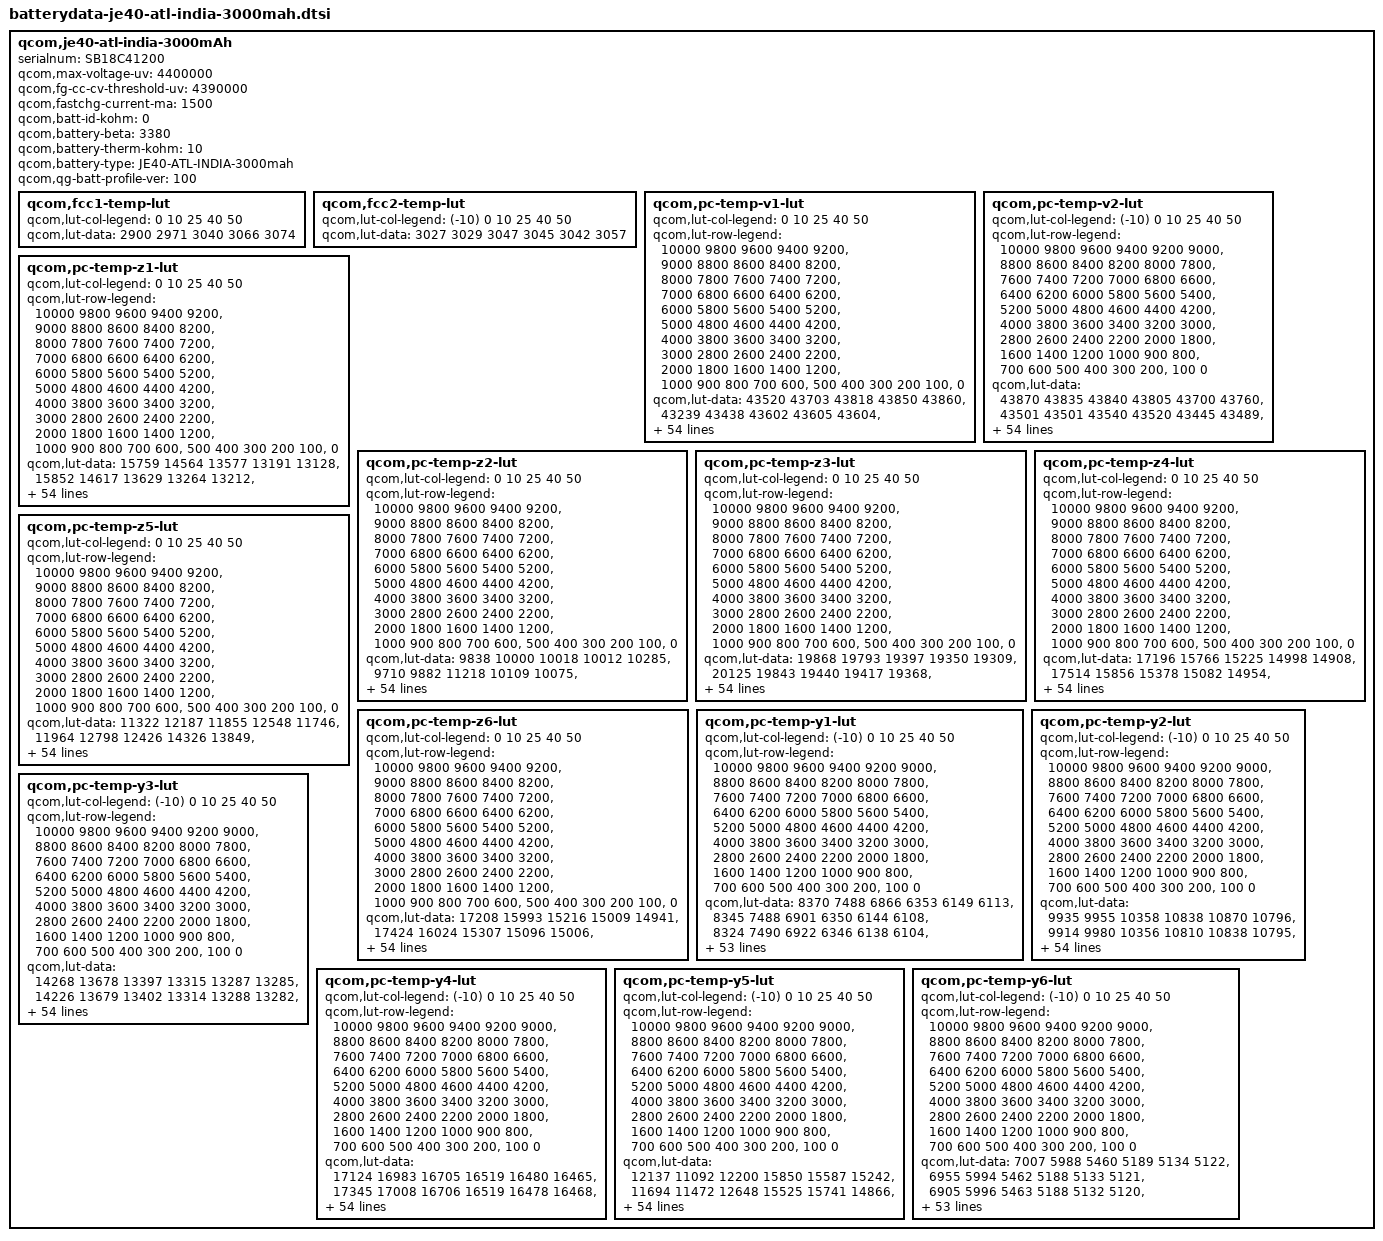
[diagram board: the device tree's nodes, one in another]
/* Copyright (c) 2018, The Linux Foundation. All rights reserved.
 *
 * This program is free software; you can redistribute it and/or modify
 * it under the terms of the GNU General Public License version 2 and
 * only version 2 as published by the Free Software Foundation.
 *
 * This program is distributed in the hope that it will be useful,
 * but WITHOUT ANY WARRANTY; without even the implied warranty of
 * MERCHANTABILITY or FITNESS FOR A PARTICULAR PURPOSE.  See the
 * GNU General Public License for more details.
 */

qcom,je40-atl-india-3000mAh {
    serialnum = "SB18C41200";
    qcom,max-voltage-uv = <4400000>;
    qcom,fg-cc-cv-threshold-uv = <4390000>;
    qcom,fastchg-current-ma = <1500>;
    qcom,batt-id-kohm = <0>;
    qcom,battery-beta = <3380>;
    qcom,battery-therm-kohm = <10>;
    qcom,battery-type = "JE40-ATL-INDIA-3000mah";
    qcom,qg-batt-profile-ver = <100>;

	qcom,fcc1-temp-lut {
		qcom,lut-col-legend = <0 10 25 40 50>;
		qcom,lut-data = <2900 2971 3040 3066 3074>;
	};

	qcom,fcc2-temp-lut {
		qcom,lut-col-legend = <(-10) 0 10 25 40 50>;
		qcom,lut-data = <3027 3029 3047 3045 3042 3057>;
	};

	qcom,pc-temp-v1-lut {
		qcom,lut-col-legend = <0 10 25 40 50>;
		qcom,lut-row-legend = <10000 9800 9600 9400 9200>,
			<9000 8800 8600 8400 8200>,
			<8000 7800 7600 7400 7200>,
			<7000 6800 6600 6400 6200>,
			<6000 5800 5600 5400 5200>,
			<5000 4800 4600 4400 4200>,
			<4000 3800 3600 3400 3200>,
			<3000 2800 2600 2400 2200>,
			<2000 1800 1600 1400 1200>,
			<1000 900 800 700 600>,
			<500 400 300 200 100>,
			<0>;
		qcom,lut-data = <43520 43703 43818 43850 43860>,
			<43239 43438 43602 43605 43604>,
			<42990 43182 43359 43372 43374>,
			<42756 42937 43108 43140 43144>,
			<42524 42699 42863 42906 42913>,
			<42295 42464 42619 42670 42678>,
			<42070 42233 42381 42435 42444>,
			<41849 42006 42147 42200 42213>,
			<41633 41783 41918 41968 41985>,
			<41428 41564 41693 41740 41757>,
			<41241 41355 41471 41515 41529>,
			<41050 41160 41258 41296 41307>,
			<40832 40962 41057 41081 41088>,
			<40594 40746 40855 40873 40877>,
			<40370 40520 40642 40666 40671>,
			<40158 40312 40429 40463 40471>,
			<39964 40120 40233 40271 40280>,
			<39805 39944 40050 40092 40099>,
			<39672 39794 39881 39922 39926>,
			<39544 39660 39741 39766 39765>,
			<39414 39522 39601 39619 39614>,
			<39287 39382 39404 39432 39433>,
			<39162 39230 39137 39155 39183>,
			<39040 39030 38915 38910 38947>,
			<38922 38792 38761 38776 38799>,
			<38809 38622 38639 38676 38685>,
			<38701 38515 38547 38579 38577>,
			<38598 38434 38475 38484 38475>,
			<38496 38374 38407 38395 38380>,
			<38405 38329 38340 38310 38291>,
			<38336 38286 38276 38232 38210>,
			<38280 38243 38217 38164 38138>,
			<38234 38203 38163 38105 38075>,
			<38197 38167 38114 38051 38016>,
			<38167 38135 38073 38003 37963>,
			<38136 38102 38034 37958 37912>,
			<38109 38073 37996 37910 37855>,
			<38076 38039 37957 37863 37792>,
			<38026 37987 37903 37802 37721>,
			<37957 37904 37815 37718 37639>,
			<37872 37805 37710 37617 37545>,
			<37754 37688 37596 37505 37434>,
			<37619 37553 37467 37376 37304>,
			<37464 37397 37310 37219 37150>,
			<37330 37256 37167 37078 37010>,
			<37236 37158 37078 36991 36927>,
			<37200 37128 37051 36968 36904>,
			<37175 37108 37033 36952 36887>,
			<37151 37093 37020 36935 36870>,
			<37110 37055 36978 36882 36807>,
			<36923 36834 36737 36622 36526>,
			<36485 36398 36304 36184 36084>,
			<35915 35822 35732 35608 35506>,
			<35141 35038 34950 34821 34715>,
			<33921 33802 33729 33596 33482>,
			<30000 30000 30000 30000 30000>;
	};

	qcom,pc-temp-v2-lut {
		qcom,lut-col-legend = <(-10) 0 10 25 40 50>;
		qcom,lut-row-legend = <10000 9800 9600 9400 9200 9000>,
			<8800 8600 8400 8200 8000 7800>,
			<7600 7400 7200 7000 6800 6600>,
			<6400 6200 6000 5800 5600 5400>,
			<5200 5000 4800 4600 4400 4200>,
			<4000 3800 3600 3400 3200 3000>,
			<2800 2600 2400 2200 2000 1800>,
			<1600 1400 1200 1000 900 800>,
			<700 600 500 400 300 200>,
			<100 0>;
		qcom,lut-data = <43870 43835 43840 43805 43700 43760>,
			<43501 43501 43540 43520 43445 43489>,
			<43164 43192 43258 43250 43195 43228>,
			<42861 42911 42996 42996 42953 42982>,
			<42587 42657 42754 42757 42719 42749>,
			<42338 42411 42515 42522 42486 42517>,
			<42122 42165 42276 42286 42253 42284>,
			<41916 41926 42039 42053 42020 42053>,
			<41674 41694 41809 41823 41791 41823>,
			<41395 41467 41582 41597 41565 41595>,
			<41162 41254 41364 41373 41342 41370>,
			<41016 41063 41155 41155 41122 41149>,
			<40877 40877 40952 40940 40907 40933>,
			<40640 40679 40751 40734 40703 40725>,
			<40281 40472 40551 40534 40505 40522>,
			<39956 40236 40341 40335 40312 40327>,
			<39699 39922 40117 40128 40117 40139>,
			<39474 39613 39889 39934 39931 39958>,
			<39289 39415 39665 39775 39765 39790>,
			<39132 39269 39444 39635 39612 39627>,
			<38978 39120 39241 39458 39432 39440>,
			<38823 38953 39054 39206 39197 39214>,
			<38675 38791 38885 38961 38969 38999>,
			<38536 38649 38736 38789 38795 38819>,
			<38405 38520 38602 38645 38645 38659>,
			<38297 38394 38481 38521 38518 38527>,
			<38213 38259 38372 38412 38411 38417>,
			<38141 38142 38272 38314 38314 38317>,
			<38073 38065 38180 38221 38225 38224>,
			<38011 38006 38095 38135 38143 38138>,
			<37952 37955 38012 38059 38070 38062>,
			<37895 37911 37930 37990 38003 37992>,
			<37839 37870 37864 37927 37938 37925>,
			<37783 37827 37818 37867 37873 37864>,
			<37728 37784 37781 37812 37806 37800>,
			<37671 37739 37743 37755 37730 37710>,
			<37609 37690 37706 37697 37641 37592>,
			<37547 37637 37663 37634 37553 37485>,
			<37481 37575 37607 37564 37472 37399>,
			<37413 37507 37540 37487 37390 37316>,
			<37345 37429 37459 37403 37303 37229>,
			<37278 37337 37357 37306 37208 37136>,
			<37210 37231 37236 37190 37091 37016>,
			<37139 37109 37102 37055 36958 36880>,
			<37058 36997 36973 36924 36850 36783>,
			<36955 36900 36890 36885 36823 36763>,
			<36902 36856 36862 36869 36810 36748>,
			<36837 36817 36834 36849 36792 36725>,
			<36744 36765 36790 36815 36747 36662>,
			<36579 36678 36695 36708 36585 36407>,
			<36300 36478 36430 36390 36172 35966>,
			<35871 36063 35924 35870 35626 35383>,
			<35255 35449 35260 35206 34908 34606>,
			<34327 34582 34328 34273 33916 33557>,
			<32758 33149 32927 33037 32736 32451>,
			<28894 29706 27951 28120 28055 28405>;
	};

	qcom,pc-temp-z1-lut {
		qcom,lut-col-legend = <0 10 25 40 50>;
		qcom,lut-row-legend = <10000 9800 9600 9400 9200>,
			<9000 8800 8600 8400 8200>,
			<8000 7800 7600 7400 7200>,
			<7000 6800 6600 6400 6200>,
			<6000 5800 5600 5400 5200>,
			<5000 4800 4600 4400 4200>,
			<4000 3800 3600 3400 3200>,
			<3000 2800 2600 2400 2200>,
			<2000 1800 1600 1400 1200>,
			<1000 900 800 700 600>,
			<500 400 300 200 100>,
			<0>;
		qcom,lut-data = <15759 14564 13577 13191 13128>,
			<15852 14617 13629 13264 13212>,
			<15836 14646 13632 13274 13223>,
			<15812 14648 13632 13279 13230>,
			<15800 14643 13626 13279 13232>,
			<15797 14632 13613 13277 13234>,
			<15795 14601 13603 13276 13235>,
			<15761 14574 13594 13276 13237>,
			<15705 14566 13587 13277 13241>,
			<15693 14560 13585 13278 13243>,
			<15734 14554 13584 13281 13245>,
			<15772 14549 13583 13282 13247>,
			<15748 14543 13583 13282 13247>,
			<15672 14515 13583 13282 13248>,
			<15617 14466 13579 13282 13249>,
			<15590 14451 13574 13280 13249>,
			<15569 14464 13574 13280 13250>,
			<15550 14477 13576 13282 13251>,
			<15533 14480 13579 13285 13252>,
			<15524 14483 13585 13288 13254>,
			<15528 14487 13594 13292 13257>,
			<15536 14499 13599 13294 13259>,
			<15541 14511 13602 13296 13262>,
			<15557 14521 13606 13298 13264>,
			<15572 14529 13613 13302 13267>,
			<15580 14536 13622 13308 13271>,
			<15587 14542 13630 13313 13276>,
			<15592 14547 13638 13317 13281>,
			<15596 14551 13646 13322 13285>,
			<15601 14554 13654 13328 13290>,
			<15612 14559 13661 13334 13294>,
			<15637 14568 13669 13340 13298>,
			<15652 14579 13675 13344 13302>,
			<15650 14590 13683 13349 13306>,
			<15646 14605 13690 13355 13310>,
			<15651 14616 13698 13361 13313>,
			<15663 14628 13707 13366 13316>,
			<15680 14642 13718 13370 13319>,
			<15711 14657 13729 13375 13322>,
			<15749 14678 13740 13380 13327>,
			<15762 14696 13750 13385 13331>,
			<15752 14706 13759 13391 13335>,
			<15747 14715 13768 13396 13338>,
			<15758 14726 13777 13401 13342>,
			<15787 14736 13792 13408 13346>,
			<15803 14732 13802 13412 13349>,
			<15782 14728 13796 13412 13351>,
			<15783 14759 13798 13414 13352>,
			<15808 14762 13804 13417 13355>,
			<15824 14730 13810 13421 13359>,
			<15866 14801 13821 13428 13366>,
			<15886 14808 13841 13440 13376>,
			<15866 14844 13865 13455 13390>,
			<15982 14889 13894 13478 13410>,
			<15982 14889 13894 13478 13410>,
			<15982 14889 13894 13478 13410>;
	};

	qcom,pc-temp-z2-lut {
		qcom,lut-col-legend = <0 10 25 40 50>;
		qcom,lut-row-legend = <10000 9800 9600 9400 9200>,
			<9000 8800 8600 8400 8200>,
			<8000 7800 7600 7400 7200>,
			<7000 6800 6600 6400 6200>,
			<6000 5800 5600 5400 5200>,
			<5000 4800 4600 4400 4200>,
			<4000 3800 3600 3400 3200>,
			<3000 2800 2600 2400 2200>,
			<2000 1800 1600 1400 1200>,
			<1000 900 800 700 600>,
			<500 400 300 200 100>,
			<0>;
		qcom,lut-data = <9838 10000 10018 10012 10285>,
			<9710 9882 11218 10109 10075>,
			<9728 9815 10902 10147 10144>,
			<9761 9799 10517 10208 10242>,
			<9787 9785 10267 10219 10270>,
			<9814 9774 10061 10202 10263>,
			<9830 9763 10001 10185 10252>,
			<9831 9757 9985 10174 10225>,
			<9831 9757 9978 10164 10182>,
			<9831 9757 10038 10156 10152>,
			<9828 9757 10146 10150 10118>,
			<9823 9759 10173 10146 10100>,
			<9805 9763 10177 10151 10089>,
			<9768 9769 10180 10159 10072>,
			<9752 9778 10185 10139 10075>,
			<9752 9795 10190 10076 10087>,
			<9753 9843 10175 10049 10095>,
			<9756 9887 10094 10055 10101>,
			<9765 9897 10047 10064 10109>,
			<9771 9898 10061 10075 10119>,
			<9765 9897 10085 10091 10138>,
			<9755 9894 10099 10119 10143>,
			<9748 9891 10111 10200 10133>,
			<9743 9892 10115 10261 10123>,
			<9740 9894 10092 10207 10130>,
			<9741 9897 10064 10100 10153>,
			<9745 9901 10063 10085 10176>,
			<9749 9904 10072 10155 10206>,
			<9754 9901 10079 10212 10225>,
			<9760 9892 10094 10220 10193>,
			<9766 9888 10109 10213 10132>,
			<9772 9894 10107 10198 10106>,
			<9779 9902 10100 10173 10076>,
			<9786 9907 10097 10161 10061>,
			<9794 9911 10101 10183 10076>,
			<9805 9915 10106 10219 10105>,
			<9821 9920 10113 10244 10157>,
			<9835 9925 10122 10269 10267>,
			<9844 9931 10135 10293 10313>,
			<9852 9938 10159 10322 10275>,
			<9860 9943 10176 10343 10235>,
			<9871 9946 10173 10344 10233>,
			<9888 9950 10170 10339 10234>,
			<9926 9967 10174 10327 10231>,
			<10138 10097 10211 10307 10230>,
			<10107 10183 10256 10260 10239>,
			<10090 10192 10253 10258 10251>,
			<10079 10224 10249 10253 10234>,
			<10029 10396 10308 10259 10260>,
			<10031 10435 10331 10349 10374>,
			<10040 10285 10344 10332 10186>,
			<9972 10255 10327 10237 10093>,
			<9811 10216 10270 10194 10018>,
			<9678 10039 10268 10115 9972>,
			<9678 10039 10268 10115 9972>,
			<9678 10039 10268 10115 9972>;
	};

	qcom,pc-temp-z3-lut {
		qcom,lut-col-legend = <0 10 25 40 50>;
		qcom,lut-row-legend = <10000 9800 9600 9400 9200>,
			<9000 8800 8600 8400 8200>,
			<8000 7800 7600 7400 7200>,
			<7000 6800 6600 6400 6200>,
			<6000 5800 5600 5400 5200>,
			<5000 4800 4600 4400 4200>,
			<4000 3800 3600 3400 3200>,
			<3000 2800 2600 2400 2200>,
			<2000 1800 1600 1400 1200>,
			<1000 900 800 700 600>,
			<500 400 300 200 100>,
			<0>;
		qcom,lut-data = <19868 19793 19397 19350 19309>,
			<20125 19843 19440 19417 19368>,
			<20140 19876 19511 19440 19394>,
			<20147 19894 19569 19454 19412>,
			<20130 19912 19581 19459 19425>,
			<20037 19914 19587 19465 19437>,
			<19957 19897 19588 19467 19444>,
			<19932 19875 19582 19467 19440>,
			<19916 19854 19575 19466 19429>,
			<19913 19832 19577 19461 19421>,
			<19913 19817 19583 19443 19414>,
			<19913 19809 19578 19431 19408>,
			<19935 19800 19558 19427 19400>,
			<19991 19784 19545 19424 19391>,
			<20016 19763 19543 19417 19385>,
			<20007 19749 19541 19402 19380>,
			<19991 19741 19535 19395 19376>,
			<19973 19735 19510 19394 19373>,
			<19949 19714 19494 19393 19370>,
			<19937 19673 19491 19390 19367>,
			<19952 19660 19489 19384 19363>,
			<19982 19680 19497 19384 19362>,
			<20008 19710 19528 19405 19369>,
			<20033 19742 19543 19423 19376>,
			<20050 19778 19534 19409 19368>,
			<20055 19791 19518 19382 19350>,
			<20057 19789 19508 19377 19348>,
			<20060 19786 19499 19387 19378>,
			<20064 19779 19496 19401 19404>,
			<20068 19765 19503 19423 19412>,
			<20064 19753 19513 19447 19417>,
			<20049 19744 19521 19449 19415>,
			<20031 19736 19530 19441 19406>,
			<20010 19731 19533 19432 19396>,
			<19986 19727 19529 19426 19387>,
			<19958 19722 19522 19420 19380>,
			<19922 19713 19517 19416 19380>,
			<19898 19704 19512 19412 19383>,
			<19892 19700 19507 19409 19384>,
			<19888 19698 19504 19408 19380>,
			<19882 19695 19500 19406 19375>,
			<19868 19690 19497 19404 19374>,
			<19848 19683 19492 19401 19375>,
			<19814 19657 19485 19399 19372>,
			<19566 19580 19468 19391 19368>,
			<19378 19527 19444 19378 19357>,
			<19375 19522 19440 19371 19352>,
			<19366 19499 19438 19367 19350>,
			<19352 19367 19388 19364 19340>,
			<19344 19361 19393 19354 19331>,
			<19360 19498 19404 19357 19369>,
			<19372 19492 19408 19367 19375>,
			<19385 19475 19395 19368 19376>,
			<19395 19390 19376 19377 19385>,
			<19395 19390 19376 19377 19385>,
			<19395 19390 19376 19377 19385>;
	};

	qcom,pc-temp-z4-lut {
		qcom,lut-col-legend = <0 10 25 40 50>;
		qcom,lut-row-legend = <10000 9800 9600 9400 9200>,
			<9000 8800 8600 8400 8200>,
			<8000 7800 7600 7400 7200>,
			<7000 6800 6600 6400 6200>,
			<6000 5800 5600 5400 5200>,
			<5000 4800 4600 4400 4200>,
			<4000 3800 3600 3400 3200>,
			<3000 2800 2600 2400 2200>,
			<2000 1800 1600 1400 1200>,
			<1000 900 800 700 600>,
			<500 400 300 200 100>,
			<0>;
		qcom,lut-data = <17196 15766 15225 14998 14908>,
			<17514 15856 15378 15082 14954>,
			<17249 15843 15284 15070 14970>,
			<16821 15689 15168 15009 14938>,
			<16563 15462 15095 14961 14907>,
			<16393 15314 15033 14924 14874>,
			<16246 15216 14982 14890 14845>,
			<16105 15142 14940 14859 14827>,
			<15977 15090 14900 14833 14813>,
			<15864 15049 14848 14816 14799>,
			<15764 15011 14798 14806 14784>,
			<15670 14972 14778 14795 14773>,
			<15570 14942 14770 14779 14767>,
			<15470 14924 14763 14765 14761>,
			<15394 14911 14757 14763 14754>,
			<15344 14898 14751 14763 14744>,
			<15302 14867 14749 14761 14734>,
			<15259 14843 14755 14744 14723>,
			<15218 14848 14754 14726 14713>,
			<15172 14861 14741 14721 14706>,
			<15108 14857 14727 14718 14702>,
			<15037 14824 14744 14725 14705>,
			<14984 14796 14824 14818 14791>,
			<14940 14822 14887 14903 14878>,
			<14911 14897 14918 14916 14893>,
			<14900 14928 14937 14923 14900>,
			<14893 14926 14934 14920 14896>,
			<14891 14923 14913 14887 14844>,
			<14893 14914 14888 14846 14790>,
			<14894 14892 14858 14800 14759>,
			<14894 14871 14825 14755 14734>,
			<14892 14856 14798 14737 14721>,
			<14890 14841 14774 14727 14712>,
			<14888 14826 14760 14723 14709>,
			<14886 14811 14753 14723 14710>,
			<14888 14801 14749 14723 14711>,
			<14898 14794 14746 14725 14714>,
			<14905 14789 14744 14730 14723>,
			<14893 14788 14744 14737 14731>,
			<14871 14790 14755 14746 14738>,
			<14864 14790 14765 14753 14743>,
			<14866 14787 14759 14747 14738>,
			<14867 14785 14749 14737 14728>,
			<14857 14796 14749 14740 14733>,
			<14971 14792 14738 14736 14730>,
			<15119 14792 14714 14711 14708>,
			<15117 14789 14704 14702 14698>,
			<15122 14805 14692 14684 14675>,
			<15129 14944 14732 14666 14661>,
			<15120 14946 14725 14678 14674>,
			<15101 14800 14741 14716 14674>,
			<15121 14826 14747 14713 14676>,
			<15137 14858 14769 14716 14680>,
			<15151 14973 14795 14710 14675>,
			<15151 14973 14795 14710 14675>,
			<15151 14973 14795 14710 14675>;
	};

	qcom,pc-temp-z5-lut {
		qcom,lut-col-legend = <0 10 25 40 50>;
		qcom,lut-row-legend = <10000 9800 9600 9400 9200>,
			<9000 8800 8600 8400 8200>,
			<8000 7800 7600 7400 7200>,
			<7000 6800 6600 6400 6200>,
			<6000 5800 5600 5400 5200>,
			<5000 4800 4600 4400 4200>,
			<4000 3800 3600 3400 3200>,
			<3000 2800 2600 2400 2200>,
			<2000 1800 1600 1400 1200>,
			<1000 900 800 700 600>,
			<500 400 300 200 100>,
			<0>;
		qcom,lut-data = <11322 12187 11855 12548 11746>,
			<11964 12798 12426 14326 13849>,
			<12134 13301 13313 14863 14593>,
			<12222 13750 14214 15292 15379>,
			<12213 14191 14808 15518 16086>,
			<12108 14392 15305 15760 16834>,
			<12032 14496 15612 16009 17268>,
			<12045 14545 15782 16324 16986>,
			<12080 14540 16021 16622 16409>,
			<12119 14521 17222 16592 16283>,
			<12162 14549 18990 16243 16492>,
			<12226 14870 19341 16055 16645>,
			<12426 15263 19100 16431 16509>,
			<12805 15513 18935 16902 16278>,
			<12993 15730 19240 16698 16263>,
			<13023 15984 19724 15855 16430>,
			<13040 16599 19590 15522 16663>,
			<13057 17080 18522 16323 17191>,
			<13096 16598 18177 17330 17876>,
			<13166 15448 19009 17717 18393>,
			<13646 15278 20536 17961 18851>,
			<14635 17106 25028 18810 19315>,
			<15806 20293 36243 23339 20113>,
			<17480 26478 41680 26974 20697>,
			<19253 36357 35146 23718 18950>,
			<20745 40012 25887 17132 15016>,
			<22198 37204 21799 15219 13991>,
			<23883 33040 19153 15069 14985>,
			<26445 29727 18335 15227 16283>,
			<28439 26533 18664 17146 17891>,
			<28370 24629 19307 20391 19893>,
			<27358 23594 20859 22479 21258>,
			<26082 22999 24049 24021 22369>,
			<24429 22993 26331 25162 23078>,
			<22470 23148 27867 26471 23530>,
			<20612 23219 28745 27543 23913>,
			<18556 22746 28648 27428 24231>,
			<17427 22149 28212 26499 24736>,
			<17744 22184 27618 25328 24863>,
			<18375 22641 26248 23442 22435>,
			<18567 22889 24816 21651 19645>,
			<18503 22541 24020 20904 19118>,
			<18489 21787 23296 20385 18929>,
			<18485 19790 21772 19465 17841>,
			<14660 17746 21401 18774 17422>,
			<11549 16164 20357 18577 16930>,
			<11511 15867 20214 18015 16739>,
			<11414 14868 20184 18226 17862>,
			<11306 11765 14733 19400 18106>,
			<11293 11768 15178 17352 15878>,
			<11491 15135 15344 14721 17835>,
			<11504 14249 14928 14881 17578>,
			<11429 13403 13875 14525 16873>,
			<11357 11748 12933 14896 17623>,
			<11357 11748 12933 14896 17623>,
			<11357 11748 12933 14896 17623>;
	};

	qcom,pc-temp-z6-lut {
		qcom,lut-col-legend = <0 10 25 40 50>;
		qcom,lut-row-legend = <10000 9800 9600 9400 9200>,
			<9000 8800 8600 8400 8200>,
			<8000 7800 7600 7400 7200>,
			<7000 6800 6600 6400 6200>,
			<6000 5800 5600 5400 5200>,
			<5000 4800 4600 4400 4200>,
			<4000 3800 3600 3400 3200>,
			<3000 2800 2600 2400 2200>,
			<2000 1800 1600 1400 1200>,
			<1000 900 800 700 600>,
			<500 400 300 200 100>,
			<0>;
		qcom,lut-data = <17208 15993 15216 15009 14941>,
			<17424 16024 15307 15096 15006>,
			<17295 16031 15298 15098 15022>,
			<17072 15979 15284 15083 15022>,
			<16904 15865 15263 15070 15022>,
			<16760 15780 15232 15056 15015>,
			<16639 15718 15205 15043 15005>,
			<16547 15666 15181 15031 14996>,
			<16470 15624 15159 15020 14985>,
			<16405 15589 15140 15008 14975>,
			<16350 15560 15123 14994 14966>,
			<16302 15538 15108 14983 14957>,
			<16257 15516 15094 14975 14949>,
			<16215 15490 15084 14968 14942>,
			<16177 15463 15079 14961 14935>,
			<16141 15443 15075 14954 14928>,
			<16108 15429 15068 14947 14922>,
			<16075 15417 15058 14939 14915>,
			<16042 15404 15049 14932 14909>,
			<16015 15392 15042 14927 14904>,
			<15994 15388 15037 14923 14900>,
			<15977 15390 15049 14927 14902>,
			<15972 15393 15102 14980 14944>,
			<15970 15417 15135 15025 14985>,
			<15969 15472 15143 15023 14985>,
			<15969 15495 15146 15015 14982>,
			<15971 15495 15143 15008 14979>,
			<15973 15495 15131 15001 14973>,
			<15979 15490 15119 14994 14966>,
			<15984 15476 15111 14988 14959>,
			<15984 15463 15105 14982 14951>,
			<15978 15454 15099 14975 14944>,
			<15971 15447 15095 14967 14936>,
			<15962 15441 15091 14961 14930>,
			<15952 15436 15087 14957 14925>,
			<15945 15432 15084 14954 14922>,
			<15938 15429 15081 14954 14923>,
			<15935 15426 15078 14955 14928>,
			<15934 15427 15078 14956 14932>,
			<15934 15433 15083 14959 14933>,
			<15934 15437 15088 14962 14933>,
			<15938 15439 15085 14960 14931>,
			<15939 15440 15080 14954 14928>,
			<15928 15438 15079 14955 14929>,
			<15865 15411 15070 14951 14927>,
			<15841 15389 15049 14934 14912>,
			<15839 15386 15043 14927 14905>,
			<15836 15381 15037 14916 14894>,
			<15834 15376 15030 14907 14882>,
			<15836 15379 15031 14909 14884>,
			<15849 15395 15046 14927 14906>,
			<15875 15413 15055 14934 14913>,
			<15910 15433 15063 14939 14918>,
			<15955 15462 15075 14947 14925>,
			<15955 15462 15075 14947 14925>,
			<15955 15462 15075 14947 14925>;
	};

	qcom,pc-temp-y1-lut {
		qcom,lut-col-legend = <(-10) 0 10 25 40 50>;
		qcom,lut-row-legend = <10000 9800 9600 9400 9200 9000>,
			<8800 8600 8400 8200 8000 7800>,
			<7600 7400 7200 7000 6800 6600>,
			<6400 6200 6000 5800 5600 5400>,
			<5200 5000 4800 4600 4400 4200>,
			<4000 3800 3600 3400 3200 3000>,
			<2800 2600 2400 2200 2000 1800>,
			<1600 1400 1200 1000 900 800>,
			<700 600 500 400 300 200>,
			<100 0>;
		qcom,lut-data = <8370 7488 6866 6353 6149 6113>,
			<8345 7488 6901 6350 6144 6108>,
			<8324 7490 6922 6346 6138 6104>,
			<8308 7494 6932 6342 6133 6100>,
			<8297 7499 6936 6337 6128 6096>,
			<8294 7502 6935 6333 6124 6093>,
			<8300 7507 6923 6329 6121 6092>,
			<8309 7512 6908 6324 6118 6090>,
			<8312 7509 6906 6319 6116 6088>,
			<8320 7498 6907 6313 6113 6085>,
			<8323 7492 6906 6310 6112 6083>,
			<8318 7492 6900 6307 6110 6082>,
			<8313 7494 6893 6305 6108 6081>,
			<8316 7498 6889 6304 6107 6080>,
			<8318 7504 6885 6302 6106 6079>,
			<8321 7509 6884 6302 6105 6078>,
			<8324 7513 6892 6303 6107 6078>,
			<8329 7516 6900 6305 6108 6078>,
			<8340 7550 6899 6306 6108 6079>,
			<8363 7644 6895 6307 6108 6080>,
			<8372 7680 6894 6309 6109 6080>,
			<8352 7601 6899 6313 6109 6080>,
			<8329 7514 6903 6317 6110 6081>,
			<8321 7500 6904 6321 6112 6081>,
			<8317 7496 6905 6325 6114 6083>,
			<8314 7495 6908 6330 6116 6084>,
			<8319 7500 6916 6334 6119 6086>,
			<8327 7505 6923 6340 6122 6088>,
			<8323 7504 6921 6346 6126 6090>,
			<8306 7502 6915 6354 6129 6092>,
			<8290 7499 6916 6361 6133 6095>,
			<8268 7494 6924 6369 6137 6099>,
			<8252 7489 6935 6376 6141 6102>,
			<8255 7488 6948 6381 6145 6105>,
			<8269 7487 6960 6386 6149 6108>,
			<8280 7485 6960 6392 6153 6110>,
			<8286 7479 6953 6397 6156 6112>,
			<8290 7475 6949 6402 6158 6113>,
			<8280 7475 6952 6407 6160 6115>,
			<8258 7476 6956 6411 6162 6117>,
			<8241 7483 6961 6416 6164 6118>,
			<8225 7496 6968 6421 6168 6120>,
			<8229 7496 6971 6426 6171 6123>,
			<8276 7482 6974 6434 6175 6126>,
			<8303 7521 6983 6444 6181 6130>,
			<8310 7536 6996 6453 6184 6132>,
			<8321 7524 6991 6457 6186 6133>,
			<8379 7571 6989 6462 6187 6133>,
			<8356 7537 7002 6474 6187 6133>,
			<8355 7539 7022 6479 6188 6136>,
			<8371 7551 7016 6480 6194 6142>,
			<8371 7543 7019 6498 6206 6153>,
			<8456 7580 7038 6541 6222 6166>,
			<8592 7602 7078 6577 6244 6187>,
			<8592 7602 7078 6577 6244 6187>,
			<8592 7602 7078 6577 6244 6187>;
	};

	qcom,pc-temp-y2-lut {
		qcom,lut-col-legend = <(-10) 0 10 25 40 50>;
		qcom,lut-row-legend = <10000 9800 9600 9400 9200 9000>,
			<8800 8600 8400 8200 8000 7800>,
			<7600 7400 7200 7000 6800 6600>,
			<6400 6200 6000 5800 5600 5400>,
			<5200 5000 4800 4600 4400 4200>,
			<4000 3800 3600 3400 3200 3000>,
			<2800 2600 2400 2200 2000 1800>,
			<1600 1400 1200 1000 900 800>,
			<700 600 500 400 300 200>,
			<100 0>;
		qcom,lut-data = <9935 9955 10358 10838 10870 10796>,
			<9914 9980 10356 10810 10838 10795>,
			<9908 10006 10353 10777 10806 10792>,
			<9915 10030 10350 10744 10778 10787>,
			<9931 10047 10347 10715 10759 10781>,
			<9952 10054 10343 10696 10752 10774>,
			<9981 10048 10338 10683 10758 10755>,
			<10021 10041 10334 10672 10768 10735>,
			<10081 10047 10337 10668 10773 10738>,
			<10177 10084 10347 10663 10774 10757>,
			<10222 10132 10353 10661 10773 10771>,
			<10219 10219 10354 10661 10771 10796>,
			<10216 10302 10355 10661 10770 10819>,
			<10233 10312 10381 10665 10778 10807>,
			<10303 10311 10456 10678 10799 10771>,
			<10365 10312 10499 10695 10827 10761>,
			<10411 10328 10511 10723 10865 10808>,
			<10442 10357 10519 10759 10912 10875>,
			<10319 10400 10529 10802 10967 10938>,
			<9905 10466 10539 10850 11029 11000>,
			<9707 10515 10552 10862 11046 11018>,
			<9693 10551 10572 10839 11014 11013>,
			<9685 10574 10594 10817 10970 10999>,
			<9679 10489 10612 10825 10924 10951>,
			<9674 10248 10630 10847 10873 10884>,
			<9670 10164 10649 10868 10862 10874>,
			<9667 10352 10671 10892 10887 10899>,
			<9665 10537 10685 10910 10925 10927>,
			<9664 10542 10688 10918 10974 10953>,
			<9663 10527 10689 10923 11034 10979>,
			<9662 10492 10693 10930 11074 11001>,
			<9662 10303 10705 10941 11112 11023>,
			<9661 10118 10712 10947 11132 11043>,
			<9661 9986 10700 10945 11121 11066>,
			<9660 9764 10679 10941 11097 11084>,
			<9659 9686 10664 10937 11075 11075>,
			<9659 9676 10653 10928 11051 11037>,
			<9658 9670 10640 10918 11026 11002>,
			<9658 9666 10621 10906 10998 10974>,
			<9657 9663 10598 10892 10972 10951>,
			<9657 9661 10575 10880 10951 10939>,
			<9657 9659 10549 10869 10929 10926>,
			<9656 9658 10507 10851 10935 10924>,
			<9656 9657 10449 10823 10941 10917>,
			<9655 9656 10404 10796 10864 10838>,
			<9655 9656 10349 10793 10866 10747>,
			<9655 9655 10316 10787 10859 10749>,
			<9655 9654 10286 10769 10848 10756>,
			<9654 9654 10255 10757 10851 10793>,
			<9654 9653 10218 10757 10847 10705>,
			<9653 9653 9955 10730 10794 10686>,
			<9652 9652 9695 10674 10740 10618>,
			<9650 9651 9665 10613 10703 10587>,
			<9648 9651 9656 10569 10648 10498>,
			<9648 9651 9656 10569 10648 10498>,
			<9648 9651 9656 10569 10648 10498>;
	};

	qcom,pc-temp-y3-lut {
		qcom,lut-col-legend = <(-10) 0 10 25 40 50>;
		qcom,lut-row-legend = <10000 9800 9600 9400 9200 9000>,
			<8800 8600 8400 8200 8000 7800>,
			<7600 7400 7200 7000 6800 6600>,
			<6400 6200 6000 5800 5600 5400>,
			<5200 5000 4800 4600 4400 4200>,
			<4000 3800 3600 3400 3200 3000>,
			<2800 2600 2400 2200 2000 1800>,
			<1600 1400 1200 1000 900 800>,
			<700 600 500 400 300 200>,
			<100 0>;
		qcom,lut-data = <14268 13678 13397 13315 13287 13285>,
			<14226 13679 13402 13314 13288 13282>,
			<14162 13680 13410 13314 13290 13281>,
			<14092 13680 13418 13314 13291 13281>,
			<14035 13680 13424 13315 13293 13282>,
			<14007 13678 13427 13316 13294 13283>,
			<14002 13666 13428 13317 13296 13287>,
			<13998 13649 13429 13319 13297 13291>,
			<13971 13653 13429 13320 13298 13292>,
			<13875 13677 13428 13321 13299 13293>,
			<13787 13689 13428 13322 13300 13294>,
			<13718 13627 13431 13325 13300 13295>,
			<13667 13547 13434 13327 13300 13296>,
			<13663 13544 13433 13327 13302 13296>,
			<13670 13567 13427 13328 13308 13296>,
			<13672 13578 13424 13328 13311 13296>,
			<13615 13552 13422 13327 13311 13299>,
			<13543 13517 13421 13327 13311 13302>,
			<13528 13501 13415 13329 13309 13302>,
			<13525 13492 13405 13335 13306 13300>,
			<13526 13479 13395 13337 13303 13298>,
			<13536 13454 13387 13329 13300 13294>,
			<13547 13431 13379 13321 13296 13290>,
			<13544 13421 13374 13316 13293 13287>,
			<13532 13413 13369 13313 13289 13284>,
			<13527 13410 13367 13312 13288 13284>,
			<13531 13398 13365 13311 13288 13283>,
			<13538 13387 13364 13311 13288 13283>,
			<13546 13384 13364 13310 13288 13282>,
			<13559 13383 13364 13309 13289 13281>,
			<13574 13383 13362 13309 13290 13281>,
			<13597 13392 13352 13311 13291 13282>,
			<13624 13406 13346 13312 13292 13283>,
			<13650 13419 13349 13313 13292 13284>,
			<13678 13433 13355 13313 13291 13286>,
			<13709 13447 13359 13314 13291 13285>,
			<13745 13460 13364 13314 13291 13283>,
			<13784 13475 13367 13314 13290 13283>,
			<13824 13498 13369 13312 13289 13283>,
			<13867 13530 13371 13309 13288 13283>,
			<13912 13567 13372 13309 13288 13284>,
			<13961 13614 13374 13310 13288 13284>,
			<14019 13668 13373 13311 13288 13285>,
			<14087 13733 13372 13312 13288 13284>,
			<14143 13802 13372 13311 13289 13282>,
			<14080 13788 13376 13313 13294 13291>,
			<14159 13862 13386 13314 13297 13295>,
			<14250 13951 13401 13318 13305 13299>,
			<14346 14038 13416 13327 13308 13301>,
			<14465 14127 13435 13331 13305 13294>,
			<14639 14216 13452 13330 13298 13296>,
			<14923 14355 13498 13332 13303 13300>,
			<15631 14607 13639 13343 13312 13305>,
			<17590 14998 13919 13357 13319 13312>,
			<17590 14998 13919 13357 13319 13312>,
			<17590 14998 13919 13357 13319 13312>;
	};

	qcom,pc-temp-y4-lut {
		qcom,lut-col-legend = <(-10) 0 10 25 40 50>;
		qcom,lut-row-legend = <10000 9800 9600 9400 9200 9000>,
			<8800 8600 8400 8200 8000 7800>,
			<7600 7400 7200 7000 6800 6600>,
			<6400 6200 6000 5800 5600 5400>,
			<5200 5000 4800 4600 4400 4200>,
			<4000 3800 3600 3400 3200 3000>,
			<2800 2600 2400 2200 2000 1800>,
			<1600 1400 1200 1000 900 800>,
			<700 600 500 400 300 200>,
			<100 0>;
		qcom,lut-data = <17124 16983 16705 16519 16480 16465>,
			<17345 17008 16706 16519 16478 16468>,
			<17479 17033 16707 16520 16477 16470>,
			<17546 17056 16709 16521 16476 16471>,
			<17571 17078 16710 16522 16476 16471>,
			<17574 17098 16711 16524 16476 16471>,
			<17494 17121 16711 16526 16477 16469>,
			<17382 17139 16711 16529 16481 16467>,
			<17373 17123 16715 16534 16484 16468>,
			<17417 17050 16728 16543 16490 16472>,
			<17474 17013 16741 16551 16498 16477>,
			<17608 17175 16752 16560 16507 16481>,
			<17747 17381 16765 16570 16517 16487>,
			<17664 17385 16806 16587 16523 16496>,
			<17294 17294 16883 16613 16527 16507>,
			<17101 17186 16911 16639 16534 16517>,
			<17090 17039 16883 16664 16548 16523>,
			<17085 16915 16836 16686 16569 16530>,
			<17095 16896 16780 16706 16602 16553>,
			<17126 16892 16709 16724 16648 16585>,
			<17138 16885 16666 16722 16658 16591>,
			<17082 16866 16640 16633 16598 16565>,
			<17010 16844 16624 16543 16531 16533>,
			<16978 16825 16618 16520 16504 16504>,
			<16956 16804 16614 16506 16486 16478>,
			<16949 16782 16611 16504 16482 16474>,
			<16950 16728 16609 16506 16486 16477>,
			<16953 16682 16607 16511 16493 16482>,
			<16955 16683 16599 16517 16501 16491>,
			<16956 16691 16588 16526 16512 16504>,
			<16956 16699 16586 16534 16524 16516>,
			<16950 16711 16586 16543 16540 16529>,
			<16944 16724 16586 16550 16550 16540>,
			<16943 16745 16590 16554 16551 16549>,
			<16943 16781 16596 16558 16551 16556>,
			<16942 16804 16605 16557 16546 16544>,
			<16940 16818 16618 16548 16520 16506>,
			<16939 16828 16630 16540 16500 16486>,
			<16944 16833 16641 16534 16496 16483>,
			<16958 16836 16650 16529 16493 16482>,
			<16973 16836 16650 16529 16495 16485>,
			<16992 16830 16649 16532 16501 16491>,
			<17014 16824 16646 16533 16501 16488>,
			<17041 16817 16640 16531 16494 16477>,
			<17047 16818 16625 16506 16471 16463>,
			<16979 16799 16630 16510 16484 16478>,
			<16992 16821 16652 16530 16501 16500>,
			<17009 16846 16683 16555 16522 16532>,
			<17030 16884 16731 16585 16549 16555>,
			<17035 16932 16790 16592 16537 16493>,
			<17026 16945 16811 16560 16494 16479>,
			<17019 16898 16822 16552 16498 16488>,
			<17139 16890 16872 16585 16522 16527>,
			<17830 16913 16971 16664 16656 16782>,
			<17830 16913 16971 16664 16656 16782>,
			<17830 16913 16971 16664 16656 16782>;
	};

	qcom,pc-temp-y5-lut {
		qcom,lut-col-legend = <(-10) 0 10 25 40 50>;
		qcom,lut-row-legend = <10000 9800 9600 9400 9200 9000>,
			<8800 8600 8400 8200 8000 7800>,
			<7600 7400 7200 7000 6800 6600>,
			<6400 6200 6000 5800 5600 5400>,
			<5200 5000 4800 4600 4400 4200>,
			<4000 3800 3600 3400 3200 3000>,
			<2800 2600 2400 2200 2000 1800>,
			<1600 1400 1200 1000 900 800>,
			<700 600 500 400 300 200>,
			<100 0>;
		qcom,lut-data = <12137 11092 12200 15850 15587 15242>,
			<11694 11472 12648 15525 15741 14866>,
			<11497 11873 13254 15174 15834 14640>,
			<11499 12231 13866 14835 15881 14526>,
			<11651 12487 14331 14546 15897 14486>,
			<11910 12579 14498 14344 15899 14493>,
			<13003 12496 14449 14227 15775 15458>,
			<14330 12380 14346 14118 15526 16675>,
			<14209 12603 14178 13921 15232 16707>,
			<12873 13599 13892 13609 14824 16281>,
			<12146 14123 13764 13381 14392 15838>,
			<12536 13247 13778 13273 13847 15448>,
			<13361 12132 13820 13203 13428 15028>,
			<14855 13085 13942 13004 13507 14460>,
			<17617 17003 14302 12544 13857 13802>,
			<18817 18855 14968 12373 13994 13615>,
			<16554 16769 17459 12657 13795 13820>,
			<13671 14329 19689 13237 13589 14006>,
			<12924 14365 19452 15045 13614 13813>,
			<12587 15219 18445 18375 13769 13386>,
			<12496 15586 17591 19575 14202 13539>,
			<12629 15405 16872 19662 16818 15802>,
			<12775 15139 16321 19661 19108 17541>,
			<12590 15260 15952 19021 18616 17476>,
			<11997 15993 15637 17686 17202 17268>,
			<11689 16210 15593 17120 16258 16965>,
			<11610 14657 15798 16924 15607 16292>,
			<11568 13060 16119 16769 15275 15557>,
			<11557 12815 17030 16466 15299 14763>,
			<11551 12640 18292 16076 15378 14095>,
			<11557 12560 18151 16092 15524 14031>,
			<11654 12773 15804 16772 15944 14184>,
			<11743 12992 14273 17524 16382 14431>,
			<11776 12820 14648 18245 16669 15211>,
			<11854 12418 15342 18933 16945 16125>,
			<11886 12304 15899 19127 17332 16490>,
			<11897 12332 16513 19064 17917 16732>,
			<11904 12376 16867 18838 18215 16794>,
			<11836 12461 16896 17753 17455 16526>,
			<11680 12584 16820 16352 16177 16139>,
			<11602 12666 16714 15805 15416 15815>,
			<11566 12724 16512 15507 14896 15563>,
			<11587 12667 15908 15470 14823 16110>,
			<11717 12326 15096 15635 15038 16219>,
			<11906 12142 14603 15999 16429 15151>,
			<12037 12115 14307 16103 15259 15731>,
			<12291 12088 14479 14832 14922 15331>,
			<12556 12367 14958 14463 15674 15130>,
			<12777 12523 15158 14793 15608 15203>,
			<12792 12726 15460 15573 15613 15726>,
			<12731 12778 14216 16301 15379 17695>,
			<12561 12615 12703 17415 17459 19428>,
			<12005 12230 12641 18740 20966 21922>,
			<10708 12336 12565 19980 21848 22352>,
			<10708 12336 12565 19980 21848 22352>,
			<10708 12336 12565 19980 21848 22352>;
	};

	qcom,pc-temp-y6-lut {
		qcom,lut-col-legend = <(-10) 0 10 25 40 50>;
		qcom,lut-row-legend = <10000 9800 9600 9400 9200 9000>,
			<8800 8600 8400 8200 8000 7800>,
			<7600 7400 7200 7000 6800 6600>,
			<6400 6200 6000 5800 5600 5400>,
			<5200 5000 4800 4600 4400 4200>,
			<4000 3800 3600 3400 3200 3000>,
			<2800 2600 2400 2200 2000 1800>,
			<1600 1400 1200 1000 900 800>,
			<700 600 500 400 300 200>,
			<100 0>;
		qcom,lut-data = <7007 5988 5460 5189 5134 5122>,
			<6955 5994 5462 5188 5133 5121>,
			<6905 5996 5463 5188 5132 5120>,
			<6858 5996 5463 5188 5133 5120>,
			<6815 5994 5462 5188 5133 5121>,
			<6776 5991 5460 5189 5134 5122>,
			<6744 5983 5456 5189 5135 5124>,
			<6712 5972 5451 5191 5137 5126>,
			<6669 5962 5450 5193 5139 5128>,
			<6611 5953 5449 5195 5141 5129>,
			<6584 5949 5449 5198 5144 5131>,
			<6584 5952 5450 5201 5146 5133>,
			<6585 5956 5453 5206 5149 5135>,
			<6564 5956 5461 5211 5153 5138>,
			<6489 5949 5475 5219 5157 5141>,
			<6431 5937 5481 5226 5162 5144>,
			<6402 5888 5473 5232 5166 5147>,
			<6382 5835 5460 5237 5171 5151>,
			<6373 5827 5441 5245 5179 5158>,
			<6368 5825 5413 5254 5189 5165>,
			<6362 5822 5393 5254 5191 5166>,
			<6352 5811 5380 5223 5171 5155>,
			<6343 5801 5371 5192 5149 5142>,
			<6340 5799 5368 5183 5138 5131>,
			<6339 5800 5366 5177 5131 5122>,
			<6339 5800 5366 5176 5129 5120>,
			<6352 5799 5367 5177 5130 5121>,
			<6372 5798 5369 5179 5132 5123>,
			<6390 5808 5372 5181 5135 5125>,
			<6410 5832 5374 5184 5139 5128>,
			<6431 5858 5376 5187 5143 5132>,
			<6453 5884 5377 5191 5149 5136>,
			<6477 5912 5378 5196 5153 5140>,
			<6502 5942 5386 5199 5153 5144>,
			<6530 5974 5400 5202 5154 5147>,
			<6559 6008 5414 5202 5153 5143>,
			<6590 6045 5430 5201 5145 5131>,
			<6623 6086 5447 5200 5139 5126>,
			<6660 6132 5464 5198 5138 5126>,
			<6701 6185 5482 5196 5136 5125>,
			<6745 6241 5502 5196 5137 5127>,
			<6792 6300 5524 5199 5139 5129>,
			<6847 6364 5548 5203 5139 5129>,
			<6911 6432 5577 5205 5138 5126>,
			<6972 6507 5591 5199 5133 5121>,
			<6931 6501 5618 5204 5141 5132>,
			<7002 6572 5659 5211 5148 5141>,
			<7083 6658 5710 5223 5160 5153>,
			<7172 6740 5768 5240 5170 5162>,
			<7281 6833 5839 5246 5164 5139>,
			<7433 6920 5887 5239 5147 5137>,
			<7677 7031 5969 5242 5154 5144>,
			<8366 7247 6189 5269 5170 5161>,
			<10250 7592 6528 5312 5216 5242>,
			<10250 7592 6528 5312 5216 5242>,
			<10250 7592 6528 5312 5216 5242>;
	};

};
